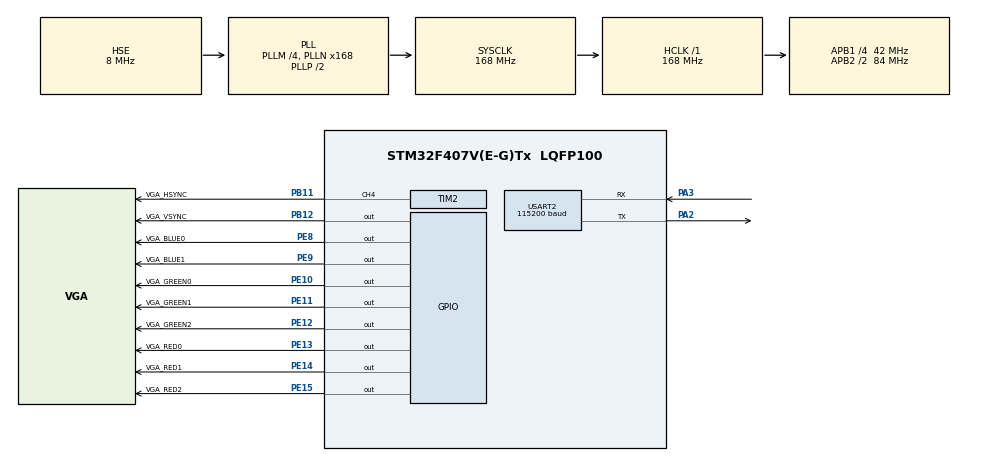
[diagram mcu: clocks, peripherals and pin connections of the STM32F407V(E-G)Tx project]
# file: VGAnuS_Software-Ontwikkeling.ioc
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Mcu.Family=STM32F4
PH0-OSC_IN.Signal=RCC_OSC_IN
PE14.GPIO_Speed=GPIO_SPEED_FREQ_VERY_HIGH
RCC.CortexFreq_Value=168000000
PE11.GPIO_Label=VGA_GREEN1
PE8.GPIO_PuPd=GPIO_NOPULL
PE9.GPIO_Speed=GPIO_SPEED_FREQ_VERY_HIGH
PE10.GPIO_PuPd=GPIO_NOPULL
Dma.TIM1_UP.0.Mode=DMA_NORMAL
PB11.Signal=S_TIM2_CH4
Dma.USART2_RX.1.MemDataAlignment=DMA_MDATAALIGN_BYTE
RCC.SYSCLKSource=RCC_SYSCLKSOURCE_PLLCLK
ProjectManager.StackSize=0x400
PB11.GPIO_Speed=GPIO_SPEED_FREQ_VERY_HIGH
Dma.USART2_TX.2.PeriphDataAlignment=DMA_PDATAALIGN_BYTE
Dma.TIM1_UP.0.MemInc=DMA_MINC_ENABLE
TIM1.Prescaler=VGA_TIM1_PRESCALE
PE11.GPIO_PuPd=GPIO_NOPULL
RCC.HCLKFreq_Value=168000000
RCC.APB2TimFreq_Value=168000000
Dma.USART2_RX.1.PeriphInc=DMA_PINC_DISABLE
Dma.USART2_RX.1.MemInc=DMA_MINC_ENABLE
RCC.AHBFreq_Value=168000000
PH0-OSC_IN.Mode=HSE-External-Oscillator
RCC.HSE_VALUE=8000000
PB3.Mode=Trace_Asynchronous_SW
Dma.USART2_TX.2.Priority=DMA_PRIORITY_LOW
PE13.GPIO_PuPd=GPIO_NOPULL
PB12.GPIO_Label=VGA_VSYNC
PE13.Signal=GPIO_Output
PE9.Signal=GPIO_Output
PA14.Mode=Trace_Asynchronous_SW
NVIC.TIM2_IRQn=true\:0\:0\:true\:false\:true\:true\:true
Dma.USART2_TX.2.MemDataAlignment=DMA_MDATAALIGN_BYTE
TIM2.Channel-PWM\ Generation3\ No\ Output=TIM_CHANNEL_3
PE10.GPIO_Speed=GPIO_SPEED_FREQ_VERY_HIGH
PE10.Signal=GPIO_Output
VP_TIM1_VS_ClockSourceINT.Mode=Internal
PH1-OSC_OUT.Mode=HSE-External-Oscillator
Mcu.Package=LQFP100
TIM2.Prescaler=VGA_TIM2_HSYNC_PRESCALE
Dma.TIM1_UP.0.Direction=DMA_MEMORY_TO_PERIPH
USART2.VirtualMode=VM_ASYNC
PE12.GPIO_Label=VGA_GREEN2
PE12.GPIO_Speed=GPIO_SPEED_FREQ_VERY_HIGH
PE8.GPIO_Speed=GPIO_SPEED_FREQ_VERY_HIGH
RCC.APB2CLKDivider=RCC_HCLK_DIV2
Dma.Request2=USART2_TX
Dma.Request1=USART2_RX
RCC.APB1TimFreq_Value=84000000
TIM1.Period=VGA_TIM1_PERIODE
Dma.USART2_RX.1.Mode=DMA_NORMAL
NVIC.DMA1_Stream6_IRQn=true\:0\:0\:false\:false\:true\:false\:true
Dma.Request0=TIM1_UP
PE10.GPIO_Label=VGA_GREEN0
PA3.Signal=USART2_RX
PE12.GPIO_PuPd=GPIO_NOPULL
RCC.PLLSourceVirtual=RCC_PLLSOURCE_HSE
Dma.USART2_TX.2.PeriphInc=DMA_PINC_DISABLE
TIM2.Channel-PWM\ Generation4\ CH4=TIM_CHANNEL_4
Dma.USART2_RX.1.Priority=DMA_PRIORITY_LOW
Dma.USART2_RX.1.FIFOMode=DMA_FIFOMODE_DISABLE
Dma.USART2_TX.2.MemInc=DMA_MINC_ENABLE
PE11.GPIO_Speed=GPIO_SPEED_FREQ_VERY_HIGH
PB11.GPIO_Label=VGA_HSYNC
PE14.GPIO_Label=VGA_RED1
TIM2.OCPolarity_3=TIM_OCPOLARITY_LOW
TIM2.OCPolarity_4=TIM_OCPOLARITY_LOW
RCC.APB1CLKDivider=RCC_HCLK_DIV4
NVIC.USART2_IRQn=true\:0\:0\:false\:false\:true\:true\:true
USART2.BaudRate=115200
PA3.Mode=Asynchronous
PA13.Signal=SYS_JTMS-SWDIO
Dma.TIM1_UP.0.PeriphDataAlignment=DMA_PDATAALIGN_BYTE
PE15.GPIO_Label=VGA_RED2
ProjectManager.TargetToolchain=STM32CubeIDE
NVIC.DMA1_Stream5_IRQn=true\:0\:0\:false\:false\:true\:false\:true
PE8.GPIO_Label=VGA_BLUE0
Dma.TIM1_UP.0.Priority=DMA_PRIORITY_VERY_HIGH
PE11.Signal=GPIO_Output
RCC.LSE_VALUE=32768
PE9.GPIO_Label=VGA_BLUE1
PB12.GPIO_Speed=GPIO_SPEED_FREQ_VERY_HIGH
Dma.USART2_RX.1.Instance=DMA1_Stream5
Dma.USART2_RX.1.Direction=DMA_PERIPH_TO_MEMORY
Dma.USART2_RX.1.PeriphDataAlignment=DMA_PDATAALIGN_BYTE
board=custom
RCC.VCOOutputFreq_Value=336000000
Dma.TIM1_UP.0.Instance=DMA2_Stream5
RCC.APB2Freq_Value=84000000
PE14.Signal=GPIO_Output
PE15.Signal=GPIO_Output
PE8.Signal=GPIO_Output
NVIC.DMA2_Stream5_IRQn=true\:0\:0\:false\:false\:true\:false\:true
PH1-OSC_OUT.Signal=RCC_OSC_OUT
PE14.GPIO_PuPd=GPIO_NOPULL
TIM2.Period=VGA_TIM2_HSYNC_PERIODE
PA13.Mode=Trace_Asynchronous_SW
Mcu.Name=STM32F407V(E-G)Tx
Dma.TIM1_UP.0.PeriphInc=DMA_PINC_DISABLE
PE12.Signal=GPIO_Output
PA2.Signal=USART2_TX
Dma.USART2_TX.2.Mode=DMA_NORMAL
RCC.48MHZClocksFreq_Value=84000000
PB3.Signal=SYS_JTDO-SWO
RCC.SYSCLKFreq_VALUE=168000000
PE13.GPIO_Label=VGA_RED0
Dma.USART2_TX.2.Instance=DMA1_Stream6
TIM2.Pulse-PWM\ Generation3\ No\ Output=VGA_TIM2_HTRIGGER_START - VGA_TIM2_DMA_DELAY
PA14.Signal=SYS_JTCK-SWCLK
PE15.GPIO_PuPd=GPIO_NOPULL
ProjectManager.HeapSize=0x200
VP_TIM2_VS_no_output3.Mode=PWM Generation3 No Output
SH.S_TIM2_CH4.0=TIM2_CH4,PWM Generation4 CH4
Dma.TIM1_UP.0.MemDataAlignment=DMA_MDATAALIGN_BYTE
RCC.HSI_VALUE=16000000
Dma.USART2_TX.2.Direction=DMA_MEMORY_TO_PERIPH
NVIC.PriorityGroup=NVIC_PRIORITYGROUP_4
PE15.GPIO_Speed=GPIO_SPEED_FREQ_VERY_HIGH
RCC.PLLM=4
RCC.PLLN=168
PE13.GPIO_Speed=GPIO_SPEED_FREQ_VERY_HIGH
Dma.USART2_TX.2.FIFOMode=DMA_FIFOMODE_DISABLE
PA2.Mode=Asynchronous
TIM2.AutoReloadPreload=TIM_AUTORELOAD_PRELOAD_DISABLE
TIM2.Pulse-PWM\ Generation4\ CH4=VGA_TIM2_HSYNC_IMP
PB12.GPIO_PuPd=GPIO_NOPULL
RCC.APB1Freq_Value=42000000
PB12.Signal=GPIO_Output
Dma.TIM1_UP.0.FIFOMode=DMA_FIFOMODE_DISABLE
PE9.GPIO_PuPd=GPIO_NOPULL

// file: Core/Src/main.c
/* USER CODE BEGIN Header */
/**
  ******************************************************************************
  * @file           : main.c
  * @brief          : Main program body
  ******************************************************************************
  * @attention
  *
  * <h2><center>&copy; Copyright (c) 2020 STMicroelectronics.
  * All rights reserved.</center></h2>
  *
  * This software component is licensed by ST under BSD 3-Clause license,
  * the "License"; You may not use this file except in compliance with the
  * License. You may obtain a copy of the License at:
  *                        opensource.org/licenses/BSD-3-Clause
  *
  ******************************************************************************
  */
/* USER CODE END Header */
#include "main.h"
#include "dma.h"
#include "tim.h"
#include "usart.h"
#include "gpio.h"

/* USER CODE BEGIN PV */

uint8_t UART2_rxBuffer[RX_BUFSIZE];

uint8_t SU_mess[] = "VGAnuSolutions\n";

/* USER CODE END PV */

void SystemClock_Config(void);

int main(void)
{

  /* MCU Configuration--------------------------------------------------------*/

  /* Reset of all peripherals, Initializes the Flash interface and the Systick. */
  HAL_Init();

  /* Configure the system clock */
  SystemClock_Config();

  /* Initialize all configured peripherals */
  MX_GPIO_Init();
  MX_DMA_Init();
  MX_TIM1_Init();
  MX_TIM2_Init();
  MX_USART2_UART_Init();
  /* USER CODE BEGIN 2 */

  API_init_IO();

  __HAL_UART_ENABLE_IT(&huart2, UART_IT_IDLE);
  HAL_UART_Receive_DMA(&huart2, UART2_rxBuffer, RX_BUFSIZE);
  HAL_UART_Transmit(&huart2, SU_mess, (uint8_t)strlen((char*)SU_mess), 10);

  /* USER CODE END 2 */

  /* Infinite loop */
  while (1)
  {

  }
}

void SystemClock_Config(void)
{
  RCC_OscInitTypeDef RCC_OscInitStruct = {0};
  RCC_ClkInitTypeDef RCC_ClkInitStruct = {0};

  /** Configure the main internal regulator output voltage
  */
  __HAL_RCC_PWR_CLK_ENABLE();
  __HAL_PWR_VOLTAGESCALING_CONFIG(PWR_REGULATOR_VOLTAGE_SCALE1);
  /** Initializes the RCC Oscillators according to the specified parameters
  * in the RCC_OscInitTypeDef structure.
  */
  RCC_OscInitStruct.OscillatorType = RCC_OSCILLATORTYPE_HSE;
  RCC_OscInitStruct.HSEState = RCC_HSE_ON;
  RCC_OscInitStruct.PLL.PLLState = RCC_PLL_ON;
  RCC_OscInitStruct.PLL.PLLSource = RCC_PLLSOURCE_HSE;
  RCC_OscInitStruct.PLL.PLLM = 4;
  RCC_OscInitStruct.PLL.PLLN = 168;
  RCC_OscInitStruct.PLL.PLLP = RCC_PLLP_DIV2;
  RCC_OscInitStruct.PLL.PLLQ = 4;
  if (HAL_RCC_OscConfig(&RCC_OscInitStruct) != HAL_OK)
  {
    Error_Handler();
  }
  /** Initializes the CPU, AHB and APB buses clocks
  */
  RCC_ClkInitStruct.ClockType = RCC_CLOCKTYPE_HCLK|RCC_CLOCKTYPE_SYSCLK
                              |RCC_CLOCKTYPE_PCLK1|RCC_CLOCKTYPE_PCLK2;
  RCC_ClkInitStruct.SYSCLKSource = RCC_SYSCLKSOURCE_PLLCLK;
  RCC_ClkInitStruct.AHBCLKDivider = RCC_SYSCLK_DIV1;
  RCC_ClkInitStruct.APB1CLKDivider = RCC_HCLK_DIV4;
  RCC_ClkInitStruct.APB2CLKDivider = RCC_HCLK_DIV2;

  if (HAL_RCC_ClockConfig(&RCC_ClkInitStruct, FLASH_LATENCY_5) != HAL_OK)
  {
    Error_Handler();
  }
}

void Error_Handler(void)
{
}

/************************ (C) COPYRIGHT STMicroelectronics *****END OF FILE****/
